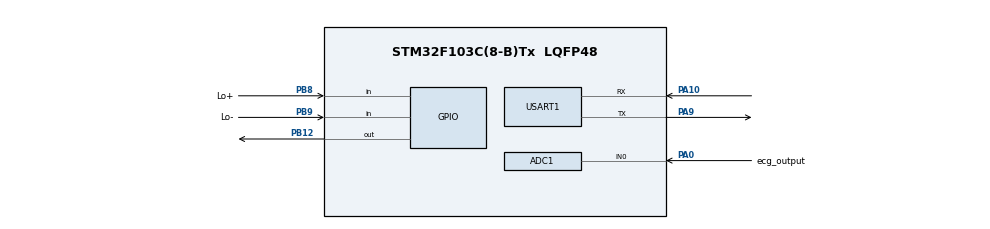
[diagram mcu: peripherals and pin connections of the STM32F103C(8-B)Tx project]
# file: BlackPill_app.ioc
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ADC1.Channel-0\#ChannelRegularConversion=ADC_CHANNEL_0
ADC1.NbrOfConversionFlag=1
ADC1.Rank-0\#ChannelRegularConversion=1
ADC1.SamplingTime-0\#ChannelRegularConversion=ADC_SAMPLETIME_1CYCLE_5
ADC1.master=1
Mcu.Family=STM32F1
Mcu.Name=STM32F103C(8-B)Tx
Mcu.Package=LQFP48
NVIC.ADC1_2_IRQn=true\:0\:0\:false\:false\:true\:true\:true
NVIC.PriorityGroup=NVIC_PRIORITYGROUP_4
NVIC.TIM2_IRQn=true\:0\:0\:false\:false\:true\:true\:true
NVIC.TIM3_IRQn=true\:0\:0\:false\:false\:true\:true\:true
NVIC.USART1_IRQn=true\:0\:0\:false\:false\:true\:true\:true
PA0-WKUP.GPIO_Label=ecg_output
PA0-WKUP.Signal=ADCx_IN0
PA10.Mode=Asynchronous
PA10.Signal=USART1_RX
PA13.Mode=Serial_Wire
PA13.Signal=SYS_JTMS-SWDIO
PA14.Mode=Serial_Wire
PA14.Signal=SYS_JTCK-SWCLK
PA9.Mode=Asynchronous
PA9.Signal=USART1_TX
PB12.Signal=GPIO_Output
PB8.GPIO_Label=Lo+
PB8.Signal=GPIO_Input
PB9.GPIO_Label=Lo-
PB9.Signal=GPIO_Input
ProjectManager.HeapSize=0x200
ProjectManager.StackSize=0x400
ProjectManager.TargetToolchain=MDK-ARM V5.27
RCC.APB1Freq_Value=8000000
RCC.APB2Freq_Value=8000000
SH.ADCx_IN0.0=ADC1_IN0,IN0
TIM2.Prescaler=8000-1
TIM3.Period=0
TIM3.Prescaler=8000-1
USART1.VirtualMode=VM_ASYNC
VP_TIM2_VS_ClockSourceINT.Mode=Internal
VP_TIM3_VS_ClockSourceINT.Mode=Internal
board=custom

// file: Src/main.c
/* USER CODE BEGIN Header */
/**
  ******************************************************************************
  * @file           : main.c
  * @brief          : Main program body
  ******************************************************************************
  * @attention
  *
  * <h2><center>&copy; Copyright (c) 2020 STMicroelectronics.
  * All rights reserved.</center></h2>
  *
  * This software component is licensed by ST under BSD 3-Clause license,
  * the "License"; You may not use this file except in compliance with the
  * License. You may obtain a copy of the License at:
  *                        opensource.org/licenses/BSD-3-Clause
  *
  ******************************************************************************
  */
/* USER CODE END Header */

#include "main.h"
#include <stdio.h>
#include <string.h>
#include <stdlib.h>

ADC_HandleTypeDef hadc1;

TIM_HandleTypeDef htim2;
TIM_HandleTypeDef htim3;

UART_HandleTypeDef huart1;

void SystemClock_Config(void);
static void MX_GPIO_Init(void);
static void MX_USART1_UART_Init(void);
static void MX_ADC1_Init(void);
static void MX_TIM2_Init(void);
static void MX_TIM3_Init(void);

/* USER CODE BEGIN 0 */
char ack_msg[] = "OK\n";
/* USER CODE END 0 */
char cmd[50];
double rate_sum = 0.0;
uint32_t beat_count = 0;
uint32_t beat_t1 = 0, beat_t2 = 0;

uint16_t beat_th = 2480;		// Threshold for a beat
uint16_t noise_pulse_level = 3600;
uint8_t prev_is_sub_thresh = 1;
uint8_t is_collecting_data = 0;
uint16_t prev_reading = 0;

// The three supported commands
char SSR[] = "SSR";
char C1MWD[] = "C1MWD";
char RHBR[] = "RHBR";

char rec_stat[2]; // receiver status

uint16_t sample_rate = 1;
uint8_t wait_for_cmd = 1;

void pc_get_cmd()
{
	memset(cmd, 0, sizeof(cmd));
  strcpy(cmd,"");
  char b[2];
  do
  {
    HAL_UART_Receive(&huart1, (uint8_t *)b, 1, HAL_MAX_DELAY);
		char c = b[0];
    if(*b != '$') strncat(cmd, &c, 1);
  } while (*b != '$');
}

void pc_ack_done(char data[], uint8_t size)
{
  HAL_UART_Transmit(&huart1, (uint8_t *)data, size, HAL_MAX_DELAY);
}

void done_ack()
{
  HAL_UART_Transmit(&huart1, (uint8_t *)ack_msg, sizeof ack_msg, HAL_MAX_DELAY);
}

void halt_transmission() {
	is_collecting_data = !is_collecting_data;
	HAL_TIM_Base_Stop_IT(&htim2);		// Stop the sampling
	HAL_TIM_Base_Stop_IT(&htim3);		// Stop the one-min timer
	wait_for_cmd = 1;
	done_ack();		// Mark end of 1-minute data
}

void HAL_UART_RxCpltCallback(UART_HandleTypeDef *huart)
{
  if (huart->Instance == USART1)
  {
    if(rec_stat[0] == '#') {
			halt_transmission();
		}
  }
}

// TIM2 --> ADC
// TIM3 -->  Minute timer
void HAL_TIM_PeriodElapsedCallback(TIM_HandleTypeDef *htim)
{
	if(!is_collecting_data) return;
  if (htim->Instance == TIM2)
  {
		// Check LO- & LO+
		if((HAL_GPIO_ReadPin(GPIOB, GPIO_PIN_8) ||
			HAL_GPIO_ReadPin(GPIOB, GPIO_PIN_9))) {
			HAL_UART_Transmit(&huart1, (uint8_t *)"!\n",
				strlen("!\n"), HAL_MAX_DELAY);
		}
		else HAL_ADC_Start_IT(&hadc1);
  }
  else if (htim->Instance == TIM3)	// We're done collecting ECG data
  {
		halt_transmission();
  }
}
void HAL_ADC_ConvCpltCallback(ADC_HandleTypeDef *hadc1)
{
	// Ignore ADC reading if we're not gonna send it
	if(!is_collecting_data) return;

  uint32_t adc_value = HAL_ADC_GetValue(hadc1);
	if(adc_value >= beat_th && prev_is_sub_thresh) {
		beat_t2 = __HAL_TIM_GET_COUNTER(&htim3);
		double new_rate = 60000.0/(beat_t2 - beat_t1);
		rate_sum += new_rate;
		++beat_count;
		beat_t1 = beat_t2;
		prev_is_sub_thresh = 0;
	}
	else {
		prev_is_sub_thresh = 1;
	}
  char out[30];
  sprintf(out, "%d\n", adc_value);
  HAL_UART_Transmit(&huart1, (uint8_t *)out, strlen(out), HAL_MAX_DELAY);
	prev_reading = adc_value;
}
void ssr(uint16_t new_ssr)
{
  sample_rate = new_ssr;
  __HAL_TIM_SET_AUTORELOAD(&htim2, (1000/new_ssr));
}

uint16_t get_1st_arg(char* _cmd)
{
  while (_cmd)
  {
    if (*_cmd == ' ')
    {
      ++_cmd;
      return atoi(_cmd);
    }
    ++_cmd;
  }
  // should never reach this
  return 0;
}
void parse_cmd()
{
  if (strncmp(cmd, SSR, strlen(SSR)) == 0)
  {
    ssr(get_1st_arg(cmd));
		wait_for_cmd = 1;
  }
  else if (strncmp(cmd, C1MWD, sizeof C1MWD) == 0)
  {
		wait_for_cmd = 0;		// Don't wait for other commands until we're done
		rate_sum = 0.0;
		beat_count = 0;
		prev_is_sub_thresh = 1;
		is_collecting_data = 1;
		__HAL_TIM_SET_COUNTER(&htim2, 0);
		__HAL_TIM_SET_COUNTER(&htim3, 0);
		HAL_TIM_Base_Start_IT(&htim2);	// Start the sampling timer
		HAL_TIM_Base_Start_IT(&htim3);	// Start the one-min timer
		HAL_UART_Receive_IT(&huart1, (uint8_t*)rec_stat, 1);
  }
  else if (strncmp(cmd, RHBR, sizeof RHBR) == 0)
  {
		char bpm[10];
		double hrate = rate_sum/beat_count;
		//hrate /= min_count;
		sprintf(bpm, "%f\n", hrate);
		HAL_UART_Transmit(&huart1, (uint8_t *)bpm, strlen(bpm), HAL_MAX_DELAY);
		wait_for_cmd = 1;
		//done_ack();
  }
}

int main(void)
{

  /* MCU Configuration--------------------------------------------------------*/

  /* Reset of all peripherals, Initializes the Flash interface and the Systick. */
  HAL_Init();

  /* Configure the system clock */
  SystemClock_Config();

  /* Initialize all configured peripherals */
  MX_GPIO_Init();
  MX_USART1_UART_Init();
  MX_ADC1_Init();
  MX_TIM2_Init();
  MX_TIM3_Init();

	__HAL_TIM_CLEAR_FLAG(&htim2, TIM_SR_UIF);
	__HAL_TIM_CLEAR_FLAG(&htim3, TIM_SR_UIF);

  __HAL_TIM_SET_AUTORELOAD(&htim2, 500 - 1);
  __HAL_TIM_SET_AUTORELOAD(&htim3, 60000 - 1);
  //HAL_TIM_Base_Start_IT(&htim2);
  //HAL_TIM_Base_Start_IT(&htim3);
  while (1)
  {
    if (wait_for_cmd)
    {
      pc_get_cmd();
      parse_cmd();
    }
  }
}

void SystemClock_Config(void)
{
  RCC_OscInitTypeDef RCC_OscInitStruct = {0};
  RCC_ClkInitTypeDef RCC_ClkInitStruct = {0};
  RCC_PeriphCLKInitTypeDef PeriphClkInit = {0};

  /** Initializes the CPU, AHB and APB busses clocks
  */
  RCC_OscInitStruct.OscillatorType = RCC_OSCILLATORTYPE_HSI;
  RCC_OscInitStruct.HSIState = RCC_HSI_ON;
  RCC_OscInitStruct.HSICalibrationValue = RCC_HSICALIBRATION_DEFAULT;
  RCC_OscInitStruct.PLL.PLLState = RCC_PLL_NONE;
  if (HAL_RCC_OscConfig(&RCC_OscInitStruct) != HAL_OK)
  {
    Error_Handler();
  }
  /** Initializes the CPU, AHB and APB busses clocks
  */
  RCC_ClkInitStruct.ClockType = RCC_CLOCKTYPE_HCLK | RCC_CLOCKTYPE_SYSCLK | RCC_CLOCKTYPE_PCLK1 | RCC_CLOCKTYPE_PCLK2;
  RCC_ClkInitStruct.SYSCLKSource = RCC_SYSCLKSOURCE_HSI;
  RCC_ClkInitStruct.AHBCLKDivider = RCC_SYSCLK_DIV1;
  RCC_ClkInitStruct.APB1CLKDivider = RCC_HCLK_DIV1;
  RCC_ClkInitStruct.APB2CLKDivider = RCC_HCLK_DIV1;

  if (HAL_RCC_ClockConfig(&RCC_ClkInitStruct, FLASH_LATENCY_0) != HAL_OK)
  {
    Error_Handler();
  }
  PeriphClkInit.PeriphClockSelection = RCC_PERIPHCLK_ADC;
  PeriphClkInit.AdcClockSelection = RCC_ADCPCLK2_DIV2;
  if (HAL_RCCEx_PeriphCLKConfig(&PeriphClkInit) != HAL_OK)
  {
    Error_Handler();
  }
}

static void MX_ADC1_Init(void)
{

  ADC_ChannelConfTypeDef sConfig = {0};

  /** Common config
  */
  hadc1.Instance = ADC1;
  hadc1.Init.ScanConvMode = ADC_SCAN_DISABLE;
  hadc1.Init.ContinuousConvMode = DISABLE;
  hadc1.Init.DiscontinuousConvMode = DISABLE;
  hadc1.Init.ExternalTrigConv = ADC_SOFTWARE_START;
  hadc1.Init.DataAlign = ADC_DATAALIGN_RIGHT;
  hadc1.Init.NbrOfConversion = 1;
  if (HAL_ADC_Init(&hadc1) != HAL_OK)
  {
    Error_Handler();
  }
  /** Configure Regular Channel
  */
  sConfig.Channel = ADC_CHANNEL_0;
  sConfig.Rank = ADC_REGULAR_RANK_1;
  sConfig.SamplingTime = ADC_SAMPLETIME_1CYCLE_5;
  if (HAL_ADC_ConfigChannel(&hadc1, &sConfig) != HAL_OK)
  {
    Error_Handler();
  }
}

static void MX_TIM2_Init(void)
{

  TIM_ClockConfigTypeDef sClockSourceConfig = {0};
  TIM_MasterConfigTypeDef sMasterConfig = {0};

  htim2.Instance = TIM2;
  htim2.Init.Prescaler = 8000 - 1;
  htim2.Init.CounterMode = TIM_COUNTERMODE_UP;
  htim2.Init.Period = 0;
  htim2.Init.ClockDivision = TIM_CLOCKDIVISION_DIV1;
  htim2.Init.AutoReloadPreload = TIM_AUTORELOAD_PRELOAD_DISABLE;
  if (HAL_TIM_Base_Init(&htim2) != HAL_OK)
  {
    Error_Handler();
  }
  sClockSourceConfig.ClockSource = TIM_CLOCKSOURCE_INTERNAL;
  if (HAL_TIM_ConfigClockSource(&htim2, &sClockSourceConfig) != HAL_OK)
  {
    Error_Handler();
  }
  sMasterConfig.MasterOutputTrigger = TIM_TRGO_RESET;
  sMasterConfig.MasterSlaveMode = TIM_MASTERSLAVEMODE_DISABLE;
  if (HAL_TIMEx_MasterConfigSynchronization(&htim2, &sMasterConfig) != HAL_OK)
  {
    Error_Handler();
  }
}

static void MX_TIM3_Init(void)
{

  TIM_ClockConfigTypeDef sClockSourceConfig = {0};
  TIM_MasterConfigTypeDef sMasterConfig = {0};

  htim3.Instance = TIM3;
  htim3.Init.Prescaler = 8000 - 1;
  htim3.Init.CounterMode = TIM_COUNTERMODE_UP;
  htim3.Init.Period = 0;
  htim3.Init.ClockDivision = TIM_CLOCKDIVISION_DIV1;
  htim3.Init.AutoReloadPreload = TIM_AUTORELOAD_PRELOAD_DISABLE;
  if (HAL_TIM_Base_Init(&htim3) != HAL_OK)
  {
    Error_Handler();
  }
  sClockSourceConfig.ClockSource = TIM_CLOCKSOURCE_INTERNAL;
  if (HAL_TIM_ConfigClockSource(&htim3, &sClockSourceConfig) != HAL_OK)
  {
    Error_Handler();
  }
  sMasterConfig.MasterOutputTrigger = TIM_TRGO_RESET;
  sMasterConfig.MasterSlaveMode = TIM_MASTERSLAVEMODE_DISABLE;
  if (HAL_TIMEx_MasterConfigSynchronization(&htim3, &sMasterConfig) != HAL_OK)
  {
    Error_Handler();
  }
}

static void MX_USART1_UART_Init(void)
{

  huart1.Instance = USART1;
  huart1.Init.BaudRate = 115200;
  huart1.Init.WordLength = UART_WORDLENGTH_8B;
  huart1.Init.StopBits = UART_STOPBITS_1;
  huart1.Init.Parity = UART_PARITY_NONE;
  huart1.Init.Mode = UART_MODE_TX_RX;
  huart1.Init.HwFlowCtl = UART_HWCONTROL_NONE;
  huart1.Init.OverSampling = UART_OVERSAMPLING_16;
  if (HAL_UART_Init(&huart1) != HAL_OK)
  {
    Error_Handler();
  }
}

static void MX_GPIO_Init(void)
{
  GPIO_InitTypeDef GPIO_InitStruct = {0};

  /* GPIO Ports Clock Enable */
  __HAL_RCC_GPIOA_CLK_ENABLE();
  __HAL_RCC_GPIOB_CLK_ENABLE();

  /*Configure GPIO pin Output Level */
  HAL_GPIO_WritePin(GPIOB, GPIO_PIN_12, GPIO_PIN_RESET);

  /*Configure GPIO pin : PB12 */
  GPIO_InitStruct.Pin = GPIO_PIN_12;
  GPIO_InitStruct.Mode = GPIO_MODE_OUTPUT_PP;
  GPIO_InitStruct.Pull = GPIO_NOPULL;
  GPIO_InitStruct.Speed = GPIO_SPEED_FREQ_LOW;
  HAL_GPIO_Init(GPIOB, &GPIO_InitStruct);

  /*Configure GPIO pins : Lo__Pin Lo_B9_Pin */
  GPIO_InitStruct.Pin = Lo__Pin | Lo_B9_Pin;
  GPIO_InitStruct.Mode = GPIO_MODE_INPUT;
  GPIO_InitStruct.Pull = GPIO_NOPULL;
  HAL_GPIO_Init(GPIOB, &GPIO_InitStruct);
}

void Error_Handler(void)
{
}

/************************ (C) COPYRIGHT STMicroelectronics *****END OF FILE****/
